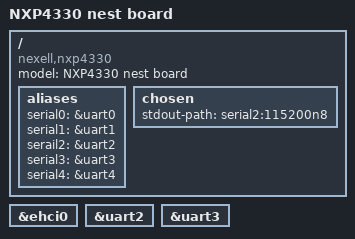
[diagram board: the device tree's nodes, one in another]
/*
 * Copyright(C) 2016 STcube Inc.,
 * All right reserved by Seungwoo Kim <ksw@stcube.com>
 *
 * Copyright 2015 Hans de Goede <hdegoede@redhat.com>
 *
 * This file is dual-licensed: you can use it either under the terms
 * of the GPL or the X11 license, at your option. Note that this dual
 * licensing only applies to this file, and not this project as a
 * whole.
 *
 *  a) This file is free software; you can redistribute it and/or
 *     modify it under the terms of the GNU General Public License as
 *     published by the Free Software Foundation; either version 2 of the
 *     License, or (at your option) any later version.
 *
 *     This file is distributed in the hope that it will be useful,
 *     but WITHOUT ANY WARRANTY; without even the implied warranty of
 *     MERCHANTABILITY or FITNESS FOR A PARTICULAR PURPOSE.  See the
 *     GNU General Public License for more details.
 *
 * Or, alternatively,
 *
 *  b) Permission is hereby granted, free of charge, to any person
 *     obtaining a copy of this software and associated documentation
 *     files (the "Software"), to deal in the Software without
 *     restriction, including without limitation the rights to use,
 *     copy, modify, merge, publish, distribute, sublicense, and/or
 *     sell copies of the Software, and to permit persons to whom the
 *     Software is furnished to do so, subject to the following
 *     conditions:
 *
 *     The above copyright notice and this permission notice shall be
 *     included in all copies or substantial portions of the Software.
 *
 *     THE SOFTWARE IS PROVIDED "AS IS", WITHOUT WARRANTY OF ANY KIND,
 *     EXPRESS OR IMPLIED, INCLUDING BUT NOT LIMITED TO THE WARRANTIES
 *     OF MERCHANTABILITY, FITNESS FOR A PARTICULAR PURPOSE AND
 *     NONINFRINGEMENT. IN NO EVENT SHALL THE AUTHORS OR COPYRIGHT
 *     HOLDERS BE LIABLE FOR ANY CLAIM, DAMAGES OR OTHER LIABILITY,
 *     WHETHER IN AN ACTION OF CONTRACT, TORT OR OTHERWISE, ARISING
 *     FROM, OUT OF OR IN CONNECTION WITH THE SOFTWARE OR THE USE OR
 *     OTHER DEALINGS IN THE SOFTWARE.
 */
/dts-v1/;
#include "nexell-nxp4330.dtsi"

/ {
	model = "NXP4330 nest board";
	compatible = "nexell,nxp4330";
	aliases {
		serial0 = &uart0;
		serial1 = &uart1;
		serail2 = &uart2;          
		serial3 = &uart3;
		serial4 = &uart4;
	};

	chosen {
		stdout-path = "serial2:115200n8";
	};
};

/*
 ksw : This configuration can be enable uarts for test.
 		also ehci enable.
 		2016.06.16
 */
&ehci0 {
	status = "okay";
};

&uart2 {
	status = "okay";
};

&uart3 {
	status = "okay";
};
